VERSION ""

NS_ :

BS_:

BU_: MASTER GEO BRIDGE MOTOR SENSOR

BO_ 100 MASTER_CONTROL: 1 MASTER
 SG_ MASTER_CONTROL_cmd : 0|1@1+ (1,0) [0|0] "" SENSOR,GEO,MOTOR,BRIDGE

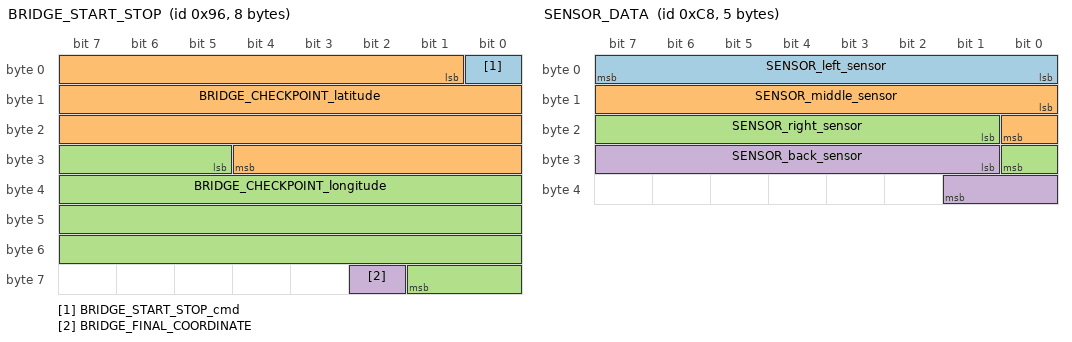
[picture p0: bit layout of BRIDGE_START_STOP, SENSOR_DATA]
BO_ 150 BRIDGE_START_STOP: 8 BRIDGE
 SG_ BRIDGE_START_STOP_cmd : 0|1@1+ (1,0) [0|0] "cmd" GEO,MASTER
 SG_ BRIDGE_CHECKPOINT_latitude : 1|28@1+ (0.000001,-90.000000) [-90|90] "" GEO,MASTER
 SG_ BRIDGE_CHECKPOINT_longitude : 29|29@1+ (0.000001,-180.000000) [-180|180] "" GEO,MASTER
 SG_ BRIDGE_FINAL_COORDINATE : 58|1@1+ (1,0) [0|0] "" GEO,MASTER

BO_ 200 SENSOR_DATA: 5 SENSOR
 SG_ SENSOR_left_sensor : 0|8@1+ (1,0) [0|0] "Inches" MASTER,BRIDGE,MOTOR
 SG_ SENSOR_middle_sensor : 8|9@1+ (1,0) [0|0] "Inches" MASTER,BRIDGE,MOTOR
 SG_ SENSOR_right_sensor : 17|8@1+ (1,0) [0|0] "Inches" MASTER,BRIDGE,MOTOR
 SG_ SENSOR_back_sensor : 25|9@1+ (1,0) [0|0] "Inches" MASTER,BRIDGE,MOTOR

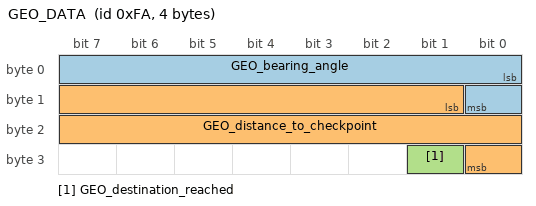
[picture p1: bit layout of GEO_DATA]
BO_ 250 GEO_DATA: 4 GEO
 SG_ GEO_bearing_angle : 0|9@1- (1,0) [-180|180] "degrees" MASTER,MOTOR
 SG_ GEO_distance_to_checkpoint : 9|16@1+ (0.01,0) [0|500] "meters" MASTER,MOTOR
 SG_ GEO_destination_reached : 25|1@1+ (1,0) [0|0] "" MASTER,MOTOR

BO_ 300 MOTOR_UPDATE: 2 MASTER
 SG_ MOTOR_speed : 0|10@1+ (0.1,-34) [-34.0|34.0] "mps" MOTOR
 SG_ MOTOR_turn_angle : 10|6@1- (1,0) [-30|30] "" MOTOR

BO_ 350 MOTOR_FEEDBACK: 2 MOTOR
 SG_ MOTOR_actual_speed : 0|10@1+ (0.1,-34) [-34.0|34.0] "mps" BRIDGE,MASTER
 SG_ sensed_battery_voltage : 10|6@1+ (0.5,0) [0|5] "volts" BRIDGE,MASTER

BO_ 400 UPDATE_CURRENT_LOCATION: 8 GEO
 SG_ UPDATE_calculated_latitude : 0|28@1+ (0.000001,-90.000000) [-90|90] "" BRIDGE,MOTOR
 SG_ UPDATE_calculated_longitude : 28|29@1+ (0.000001,-180.000000) [-180|180] "" BRIDGE,MOTOR

BO_ 450 UPDATE_COMPASS_BEARING: 2 GEO
 SG_ COMPASS_bearing_angle : 0|9@1+ (1,0) [0|360] "degrees" MOTOR

BO_ 500 BRIDGE_HB: 1 BRIDGE
 SG_ BRIDGE_heartbeat : 0|2@1+ (1,0) [0|0] "" MASTER

BO_ 510 SENSOR_HB: 1 SENSOR
 SG_ SENSOR_heartbeat : 0|2@1+ (1,0) [0|0] "" MASTER

BO_ 520 GEO_HB: 1 GEO
 SG_ GEO_heartbeat : 0|2@1+ (1,0) [0|0] "" MASTER

BO_ 530 MOTOR_HB: 1 MOTOR
 SG_ MOTOR_heartbeat : 0|2@1+ (1,0) [0|0] "" MASTER

CM_ BU_ MASTER  "The Master controller driving the car";
CM_ BU_ MOTOR   "The Motor controller of the car";
CM_ BU_ SENSOR  "The Sensor controller of the car";
CM_ BU_ BRIDGE  "The Bridge controller (Bluetooth module) of the car";
CM_ BU_ GEO     "The GEO (GPS + Compass) controller of the car";

BA_DEF_ "BusType" STRING ;
BA_DEF_ BO_ "GenMsgCycleTime" INT 0 0;
BA_DEF_ SG_ "FieldType" STRING ;

BA_DEF_DEF_ "BusType" "CAN";
BA_DEF_DEF_ "FieldType" "";
BA_DEF_DEF_ "GenMsgCycleTime" 0;

BA_ "GenMsgCycleTime" BO_ 150 100;
BA_ "GenMsgCycleTime" BO_ 100 100;
BA_ "GenMsgCycleTime" BO_ 200 100;
BA_ "GenMsgCycleTime" BO_ 400 100;
BA_ "GenMsgCycleTime" BO_ 250 100;
BA_ "FieldType" SG_ 100 MASTER_CONTROL_cmd "MASTER_CONTROL_cmd";

VAL_ 100 MASTER_CONTROL_cmd 1 "DRIVER_HEARTBEAT_cmd_START" 0 "DRIVER_HEARTBEAT_cmd_RESET" ;
